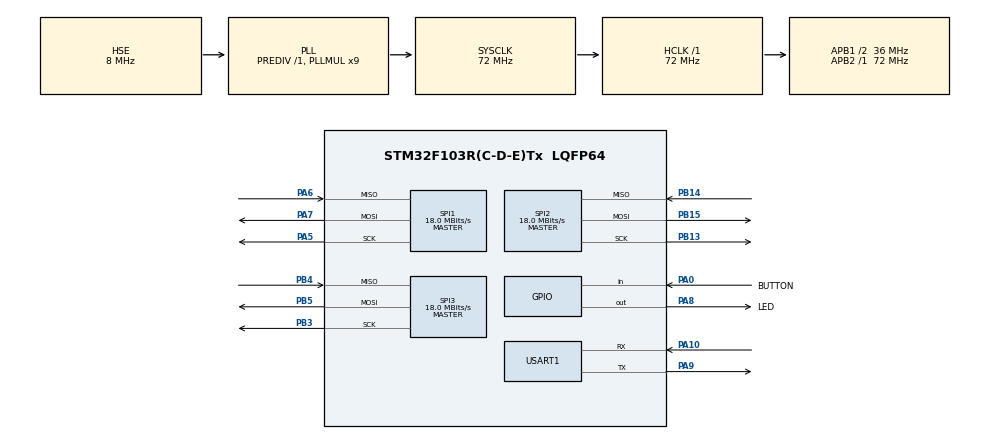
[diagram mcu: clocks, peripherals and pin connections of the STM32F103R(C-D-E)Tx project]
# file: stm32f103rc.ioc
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ADC1.Channel-0\#ChannelRegularConversion=ADC_CHANNEL_TEMPSENSOR
ADC1.NbrOfConversionFlag=1
ADC1.Rank-0\#ChannelRegularConversion=1
ADC1.SamplingTime-0\#ChannelRegularConversion=ADC_SAMPLETIME_1CYCLE_5
ADC1.master=1
Mcu.Family=STM32F1
Mcu.Name=STM32F103R(C-D-E)Tx
Mcu.Package=LQFP64
NVIC.PriorityGroup=NVIC_PRIORITYGROUP_4
PA0-WKUP.GPIO_Label=BUTTON
PA0-WKUP.Signal=GPIO_Input
PA10.Mode=Asynchronous
PA10.Signal=USART1_RX
PA5.Mode=Full_Duplex_Master
PA5.Signal=SPI1_SCK
PA6.Mode=Full_Duplex_Master
PA6.Signal=SPI1_MISO
PA7.Mode=Full_Duplex_Master
PA7.Signal=SPI1_MOSI
PA8.GPIO_Label=LED
PA8.Signal=GPIO_Output
PA9.Mode=Asynchronous
PA9.Signal=USART1_TX
PB13.Mode=Full_Duplex_Master
PB13.Signal=SPI2_SCK
PB14.Mode=Full_Duplex_Master
PB14.Signal=SPI2_MISO
PB15.Mode=Full_Duplex_Master
PB15.Signal=SPI2_MOSI
PB3.Mode=Full_Duplex_Master
PB3.Signal=SPI3_SCK
PB4.Mode=Full_Duplex_Master
PB4.Signal=SPI3_MISO
PB5.Mode=Full_Duplex_Master
PB5.Signal=SPI3_MOSI
PC14-OSC32_IN.Mode=LSE-External-Oscillator
PC14-OSC32_IN.Signal=RCC_OSC32_IN
PC15-OSC32_OUT.Mode=LSE-External-Oscillator
PC15-OSC32_OUT.Signal=RCC_OSC32_OUT
PD0-OSC_IN.Mode=HSE-External-Oscillator
PD0-OSC_IN.Signal=RCC_OSC_IN
PD1-OSC_OUT.Mode=HSE-External-Oscillator
PD1-OSC_OUT.Signal=RCC_OSC_OUT
ProjectManager.HeapSize=0x200
ProjectManager.StackSize=0x400
ProjectManager.TargetToolchain=TrueSTUDIO
RCC.ADCPresc=RCC_ADCPCLK2_DIV6
RCC.AHBFreq_Value=72000000
RCC.APB1CLKDivider=RCC_HCLK_DIV2
RCC.APB1Freq_Value=36000000
RCC.APB1TimFreq_Value=72000000
RCC.APB2Freq_Value=72000000
RCC.APB2TimFreq_Value=72000000
RCC.HCLKFreq_Value=72000000
RCC.PLLMUL=RCC_PLL_MUL9
RCC.PLLSourceVirtual=RCC_PLLSOURCE_HSE
RCC.SYSCLKFreq_VALUE=72000000
RCC.SYSCLKSource=RCC_SYSCLKSOURCE_PLLCLK
RCC.USBFreq_Value=72000000
SPI1.BaudRatePrescaler=SPI_BAUDRATEPRESCALER_4
SPI1.CalculateBaudRate=18.0 MBits/s
SPI1.Direction=SPI_DIRECTION_2LINES
SPI1.Mode=SPI_MODE_MASTER
SPI1.VirtualType=VM_MASTER
SPI2.BaudRatePrescaler=SPI_BAUDRATEPRESCALER_2
SPI2.CalculateBaudRate=18.0 MBits/s
SPI2.Direction=SPI_DIRECTION_2LINES
SPI2.Mode=SPI_MODE_MASTER
SPI2.VirtualType=VM_MASTER
SPI3.BaudRatePrescaler=SPI_BAUDRATEPRESCALER_2
SPI3.CalculateBaudRate=18.0 MBits/s
SPI3.Direction=SPI_DIRECTION_2LINES
SPI3.Mode=SPI_MODE_MASTER
SPI3.VirtualType=VM_MASTER
USART1.VirtualMode=VM_ASYNC
VP_ADC1_TempSens_Input.Mode=IN-TempSens
VP_IWDG_VS_IWDG.Mode=IWDG_Activate
VP_SYS_VS_ND.Mode=No_Debug
board=custom

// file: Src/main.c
/**
  ******************************************************************************
  * @file           : main.c
  * @brief          : Main program body
  ******************************************************************************
  ** This notice applies to any and all portions of this file
  * that are not between comment pairs USER CODE BEGIN and
  * USER CODE END. Other portions of this file, whether
  * inserted by the user or by software development tools
  * are owned by their respective copyright owners.
  *
  * COPYRIGHT(c) 2018 STMicroelectronics
  *
  * Redistribution and use in source and binary forms, with or without modification,
  * are permitted provided that the following conditions are met:
  *   1. Redistributions of source code must retain the above copyright notice,
  *      this list of conditions and the following disclaimer.
  *   2. Redistributions in binary form must reproduce the above copyright notice,
  *      this list of conditions and the following disclaimer in the documentation
  *      and/or other materials provided with the distribution.
  *   3. Neither the name of STMicroelectronics nor the names of its contributors
  *      may be used to endorse or promote products derived from this software
  *      without specific prior written permission.
  *
  * THIS SOFTWARE IS PROVIDED BY THE COPYRIGHT HOLDERS AND CONTRIBUTORS "AS IS"
  * AND ANY EXPRESS OR IMPLIED WARRANTIES, INCLUDING, BUT NOT LIMITED TO, THE
  * IMPLIED WARRANTIES OF MERCHANTABILITY AND FITNESS FOR A PARTICULAR PURPOSE ARE
  * DISCLAIMED. IN NO EVENT SHALL THE COPYRIGHT HOLDER OR CONTRIBUTORS BE LIABLE
  * FOR ANY DIRECT, INDIRECT, INCIDENTAL, SPECIAL, EXEMPLARY, OR CONSEQUENTIAL
  * DAMAGES (INCLUDING, BUT NOT LIMITED TO, PROCUREMENT OF SUBSTITUTE GOODS OR
  * SERVICES; LOSS OF USE, DATA, OR PROFITS; OR BUSINESS INTERRUPTION) HOWEVER
  * CAUSED AND ON ANY THEORY OF LIABILITY, WHETHER IN CONTRACT, STRICT LIABILITY,
  * OR TORT (INCLUDING NEGLIGENCE OR OTHERWISE) ARISING IN ANY WAY OUT OF THE USE
  * OF THIS SOFTWARE, EVEN IF ADVISED OF THE POSSIBILITY OF SUCH DAMAGE.
  *
  ******************************************************************************
  */
#include "main.h"
#include "stm32f1xx_hal.h"
#include "adc.h"
#include "iwdg.h"
#include "spi.h"
#include "usart.h"
#include "gpio.h"

/* USER CODE BEGIN PV */
/* Private variables ---------------------------------------------------------*/

/* USER CODE END PV */

void SystemClock_Config(void);

/* USER CODE BEGIN PFP */
/* Private function prototypes -----------------------------------------------*/

/* USER CODE END PFP */

int main(void)
{

  /* MCU Configuration----------------------------------------------------------*/

  /* Reset of all peripherals, Initializes the Flash interface and the Systick. */
  HAL_Init();

  /* Configure the system clock */
  SystemClock_Config();

  /* Initialize all configured peripherals */
  MX_GPIO_Init();
  MX_SPI1_Init();
  MX_SPI2_Init();
  MX_USART1_UART_Init();
  MX_IWDG_Init();
  MX_ADC1_Init();
  MX_SPI3_Init();

  /* Infinite loop */
  /* USER CODE BEGIN WHILE */
  while (1)
  {
    HAL_GPIO_TogglePin(LED_GPIO_Port, LED_Pin);
    for(unsigned int i = 0; i < 0xffff * 100; i++);

  /* USER CODE END WHILE */

  }

}

void SystemClock_Config(void)
{

  RCC_OscInitTypeDef RCC_OscInitStruct;
  RCC_ClkInitTypeDef RCC_ClkInitStruct;
  RCC_PeriphCLKInitTypeDef PeriphClkInit;

    /**Initializes the CPU, AHB and APB busses clocks
    */
  RCC_OscInitStruct.OscillatorType = RCC_OSCILLATORTYPE_LSI|RCC_OSCILLATORTYPE_HSE;
  RCC_OscInitStruct.HSEState = RCC_HSE_ON;
  RCC_OscInitStruct.HSEPredivValue = RCC_HSE_PREDIV_DIV1;
  RCC_OscInitStruct.HSIState = RCC_HSI_ON;
  RCC_OscInitStruct.LSIState = RCC_LSI_ON;
  RCC_OscInitStruct.PLL.PLLState = RCC_PLL_ON;
  RCC_OscInitStruct.PLL.PLLSource = RCC_PLLSOURCE_HSE;
  RCC_OscInitStruct.PLL.PLLMUL = RCC_PLL_MUL9;
  if (HAL_RCC_OscConfig(&RCC_OscInitStruct) != HAL_OK)
  {
    _Error_Handler(__FILE__, __LINE__);
  }

    /**Initializes the CPU, AHB and APB busses clocks
    */
  RCC_ClkInitStruct.ClockType = RCC_CLOCKTYPE_HCLK|RCC_CLOCKTYPE_SYSCLK
                              |RCC_CLOCKTYPE_PCLK1|RCC_CLOCKTYPE_PCLK2;
  RCC_ClkInitStruct.SYSCLKSource = RCC_SYSCLKSOURCE_PLLCLK;
  RCC_ClkInitStruct.AHBCLKDivider = RCC_SYSCLK_DIV1;
  RCC_ClkInitStruct.APB1CLKDivider = RCC_HCLK_DIV2;
  RCC_ClkInitStruct.APB2CLKDivider = RCC_HCLK_DIV1;

  if (HAL_RCC_ClockConfig(&RCC_ClkInitStruct, FLASH_LATENCY_2) != HAL_OK)
  {
    _Error_Handler(__FILE__, __LINE__);
  }

  PeriphClkInit.PeriphClockSelection = RCC_PERIPHCLK_ADC;
  PeriphClkInit.AdcClockSelection = RCC_ADCPCLK2_DIV6;
  if (HAL_RCCEx_PeriphCLKConfig(&PeriphClkInit) != HAL_OK)
  {
    _Error_Handler(__FILE__, __LINE__);
  }

    /**Configure the Systick interrupt time
    */
  HAL_SYSTICK_Config(HAL_RCC_GetHCLKFreq()/1000);

    /**Configure the Systick
    */
  HAL_SYSTICK_CLKSourceConfig(SYSTICK_CLKSOURCE_HCLK);

  /* SysTick_IRQn interrupt configuration */
  HAL_NVIC_SetPriority(SysTick_IRQn, 0, 0);
}

void _Error_Handler(char *file, int line)
{
  while(1)
  {
  }
}

/************************ (C) COPYRIGHT STMicroelectronics *****END OF FILE****/
